# STM32F030x8 register map
File version: 1.0
Registers are 32-bit, read-write, reset 0x0 unless marked. A register's access mark holds for its fields unless they carry their own. Offsets are from the block's base; lines under a group give offsets from that group; [hi:lo] are bit positions; {n}, {i} and the like mark numbered series; 'fields as' and 'values as' point back to an identical list; <NAME> marks a mode.

## Memory map
0x1FFFF800 OB — Option Bytes Registers
0x40000400 TIM3 — TIM
0x40001000 TIM6 — TIM
0x40002000 TIM14 — TIM
0x40002800 RTC — Real-Time Clock
0x40002C00 WWDG — Window WATCHDOG
0x40003000 IWDG — Independent WATCHDOG
0x40003800 SPI2 — Serial Peripheral Interface
0x40004400 USART2 — Universal Synchronous Asynchronous Receiver Transmitter
0x40005400 I2C1 — Inter-integrated Circuit Interface
0x40005800 I2C2 — Inter-integrated Circuit Interface
0x40007000 PWR — Power Control
0x40010000 SYSCFG — SysTem Configuration
0x40010400 EXTI — External Interrupt/Event Controller
0x40012400 ADC1 — Analog to Digital Converter
0x40012708 ADC
0x40012C00 TIM1 — TIM
0x40013000 SPI1 — Serial Peripheral Interface
0x40013800 USART1 — Universal Synchronous Asynchronous Receiver Transmitter
0x40014000 TIM15 — TIM
0x40014400 TIM16 — TIM
0x40014800 TIM17 — TIM
0x40015800 DBGMCU — Debug MCU
0x40020000 DMA1
0x40021000 RCC — Reset and Clock Control
0x40022000 FLASH — FLASH Registers
0x40023000 CRC — CRC calculation unit
0x48000000 GPIOA — General Purpose I/O
0x48000400 GPIOB — General Purpose I/O
0x48000800 GPIOC — General Purpose I/O
0x48000C00 GPIOD — General Purpose I/O
0x48001400 GPIOF — General Purpose I/O

## Interrupts
0 WWDG — Window WatchDog Interrupt
2 RTC — RTC Interrupt through EXTI Lines 17, 19 and 20
3 FLASH — FLASH global Interrupt
4 RCC — RCC global Interrupt
5 EXTI0_1 (EXTI) — EXTI Line 0 and 1 Interrupt
6 EXTI2_3 (EXTI) — EXTI Line 2 and 3 Interrupt
7 EXTI4_15 (EXTI) — EXTI Line 4 to 15 Interrupt
9 DMA1_Channel1 (DMA1) — DMA1 Channel 1 Interrupt
10 DMA1_Channel2_3 (DMA1) — DMA1 Channel 2 and Channel 3 Interrupt
11 DMA1_Channel4_5 (DMA1) — DMA1 Channel 4 and Channel 5 Interrupt
12 ADC1 — ADC1 Interrupt
13 TIM1_BRK_UP_TRG_COM (TIM1) — TIM1 Break, Update, Trigger and Commutation Interrupt
14 TIM1_CC (TIM1) — TIM1 Capture Compare Interrupt
16 TIM3 — TIM3 global Interrupt
17 TIM6 — TIM6 global Interrupt
19 TIM14 — TIM14 global Interrupt
20 TIM15 — TIM15 global Interrupt
21 TIM16 — TIM16 global Interrupt
22 TIM17 — TIM17 global Interrupt
23 I2C1 — I2C1 Event Interrupt
24 I2C2 — I2C2 Event Interrupt
25 SPI1 — SPI1 global Interrupt
26 SPI2 — SPI2 global Interrupt
27 USART1 — USART1 global Interrupt
28 USART2 — USART2 global Interrupt

## OB — Option Bytes Registers
Base 0x1FFFF800
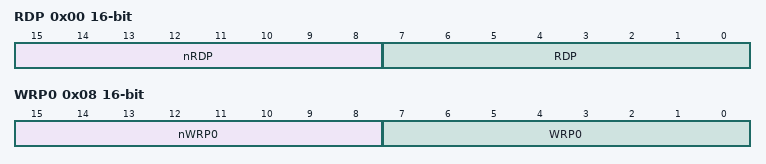
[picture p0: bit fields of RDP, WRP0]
0x00 RDP 16-bit — FLASH option byte Read protection
  [15:8] nRDP — Read protection complemented option byte
  [7:0] RDP — Read protection option byte
0x02 USER 16-bit — FLASH option byte user options
  [31:24] nUSER — User complemented option byte
  [23:16] USER — User option byte
0x04 DATA0 16-bit — User data byte 0 (stored in FLASH_OBR[23:16])
0x06 DATA1 16-bit — User data byte 1 (stored in FLASH_OBR[31:24])
0x08 WRP0 16-bit — FLASH option byte write protection 0
  [15:8] nWRP0 — Flash memory write protection complemented option bytes
  [7:0] WRP0 — Flash memory write protection option bytes
0x0A WRP1 16-bit — FLASH option byte write protection 1
  [31:24] nWRP1 — Flash memory write protection complemented option bytes
  [23:16] WRP1 — Flash memory write protection option bytes

## TIM6 — TIM
Base 0x40001000
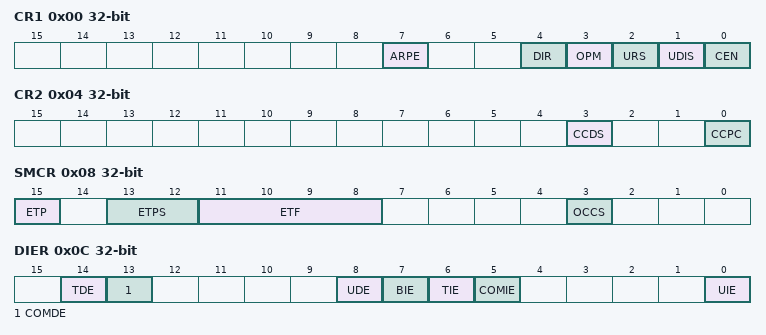
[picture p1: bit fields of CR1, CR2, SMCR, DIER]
0x00 CR1 — TIM control register 1
  [7] ARPE — Auto-reload preload enable
  [4] DIR — Direction
    0=UP (Timer counter counts up); 1=DOWN (Timer counter counts down)
  [3] OPM — One pulse mode
    1=SINGLE (Counter stops counting at the next update event); 0=REPETITIVE (Counter is not stopped at update event)
  [2] URS — Update request source
    0=REGULAR (Counter overflow/underflow, Setting the UG bit or Update generation through the slave mode controller generates an update request); 1=COUNTER (Only counter overflow/underflow generates an update request)
  [1] UDIS — Update disable
  [0] CEN — Counter enable
0x04 CR2 — TIM control register 2
  [3] CCDS — Capture/Compare DMA Selection
    0=CC (CCx DMA request sent when CCx event occurs); 1=UPDATE (CCx DMA requests sent when update event occurs)
  [0] CCPC — Capture/Compare Preloaded Control
0x08 SMCR — TIM slave Mode Control register
  [15] ETP — External trigger polarity
  [13:12] ETPS — ETPS[1:0] bits (External trigger prescaler)
  [11:8] ETF — ETF[3:0] bits (External trigger filter)
  [3] OCCS — OCREF clear selection
    0=OCREF_CLR (OCREF_CLR_INT is connected to the OCREF_CLR input); 1=ETR (OCREF_CLR_INT is connected to ETRF)
0x0C DIER — TIM DMA/interrupt enable register
  [14] TDE — Trigger DMA request enable
  [13] COMDE — COM DMA request enable
  [8] UDE — Update DMA request enable
  [7] BIE — Break interrupt enable
  [6] TIE — Trigger interrupt enable
  [5] COMIE — COM interrupt enable
  [0] UIE — Update interrupt enable
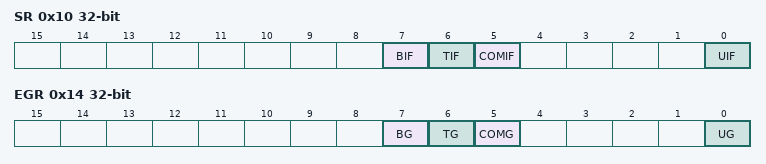
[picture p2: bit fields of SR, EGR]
0x10 SR — TIM status register
  [7] BIF — Break interrupt Flag
  [6] TIF — Trigger interrupt Flag
  [5] COMIF — COM interrupt Flag
  [0] UIF — Update interrupt Flag
0x14 EGR — TIM event generation register
  [7] BG — Break Generation
  [6] TG — Trigger Generation
  [5] COMG — Capture/Compare Control Update Generation
  [0] UG — Update Generation
0x24 CNT — TIM counter register
  [15:0] CNT — Counter Value
0x28 PSC — TIM prescaler register
  [15:0] PSC — Prescaler Value
0x2C ARR — TIM auto-reload register
  [15:0] ARR — actual auto-reload Value
0x4C DMAR — TIM DMA address for full transfer register
  [15:0] DMAB — DMA register for burst accesses
0x50 OR — TIM option register
